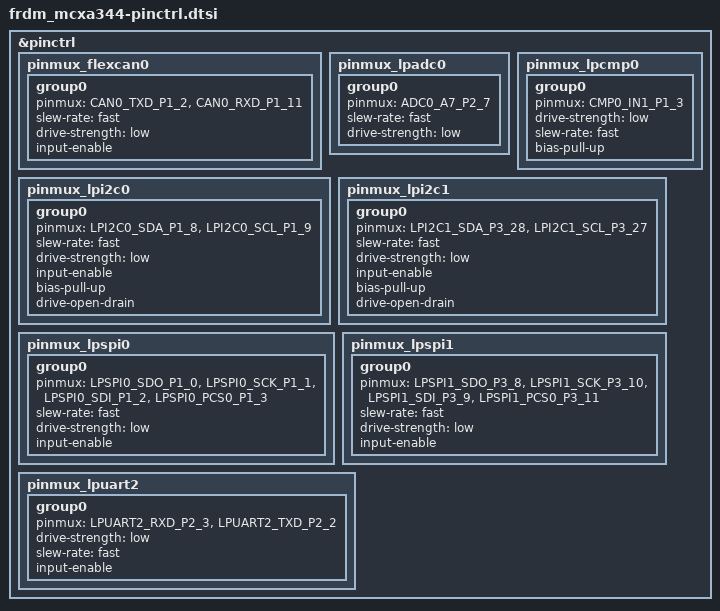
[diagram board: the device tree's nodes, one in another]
/*
 * Copyright 2025 NXP
 * SPDX-License-Identifier: Apache-2.0
 */

#include <nxp/mcx/MCXA344VLL-pinctrl.h>

&pinctrl {
	pinmux_flexcan0: pinmux_flexcan0 {
		group0 {
			pinmux = <CAN0_TXD_P1_2>,
				 <CAN0_RXD_P1_11>;
			slew-rate = "fast";
			drive-strength = "low";
			input-enable;
		};
	};

	pinmux_lpadc0: pinmux_lpadc0 {
		group0 {
			pinmux = <ADC0_A7_P2_7>;
			slew-rate = "fast";
			drive-strength = "low";
		};
	};

	pinmux_lpcmp0: pinmux_lpcmp0 {
		group0 {
			pinmux = <CMP0_IN1_P1_3>;
			drive-strength = "low";
			slew-rate = "fast";
			bias-pull-up;
		};
	};

	pinmux_lpi2c0: pinmux_lpi2c0 {
		group0 {
			pinmux = <LPI2C0_SDA_P1_8>,
				 <LPI2C0_SCL_P1_9>;
			slew-rate = "fast";
			drive-strength = "low";
			input-enable;
			bias-pull-up;
			drive-open-drain;
		};
	};

	pinmux_lpi2c1: pinmux_lpi2c1 {
		group0 {
			pinmux = <LPI2C1_SDA_P3_28>,
				 <LPI2C1_SCL_P3_27>;
			slew-rate = "fast";
			drive-strength = "low";
			input-enable;
			bias-pull-up;
			drive-open-drain;
		};
	};

	pinmux_lpspi0: pinmux_lpspi0 {
		group0 {
			pinmux = <LPSPI0_SDO_P1_0>,
				 <LPSPI0_SCK_P1_1>,
				 <LPSPI0_SDI_P1_2>,
				 <LPSPI0_PCS0_P1_3>;
			slew-rate = "fast";
			drive-strength = "low";
			input-enable;
		};
	};

	pinmux_lpspi1: pinmux_lpspi1 {
		group0 {
			pinmux = <LPSPI1_SDO_P3_8>,
				 <LPSPI1_SCK_P3_10>,
				 <LPSPI1_SDI_P3_9>,
				 <LPSPI1_PCS0_P3_11>;
			slew-rate = "fast";
			drive-strength = "low";
			input-enable;
		};
	};

	pinmux_lpuart2: pinmux_lpuart2 {
		group0 {
			pinmux = <LPUART2_RXD_P2_3>,
				 <LPUART2_TXD_P2_2>;
			drive-strength = "low";
			slew-rate = "fast";
			input-enable;
		};
	};
};
